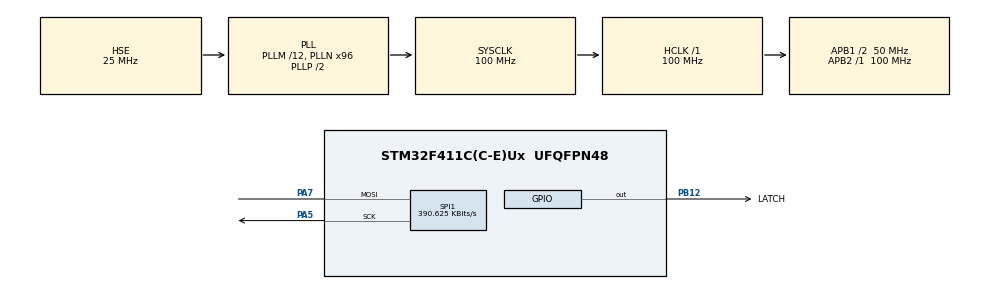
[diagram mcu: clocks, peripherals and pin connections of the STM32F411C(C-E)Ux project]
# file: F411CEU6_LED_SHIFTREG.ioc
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Mcu.Family=STM32F4
Mcu.Name=STM32F411C(C-E)Ux
Mcu.Package=UFQFPN48
NVIC.PriorityGroup=NVIC_PRIORITYGROUP_4
PA13.Mode=Serial_Wire
PA13.Signal=SYS_JTMS-SWDIO
PA14.Mode=Serial_Wire
PA14.Signal=SYS_JTCK-SWCLK
PA5.Mode=Simplex_Bidirectional_Master
PA5.Signal=SPI1_SCK
PA7.Mode=Simplex_Bidirectional_Master
PA7.Signal=SPI1_MOSI
PB12.GPIO_Label=LATCH
PB12.Signal=GPIO_Output
PH0\ -\ OSC_IN.Mode=HSE-External-Oscillator
PH0\ -\ OSC_IN.Signal=RCC_OSC_IN
PH1\ -\ OSC_OUT.Mode=HSE-External-Oscillator
PH1\ -\ OSC_OUT.Signal=RCC_OSC_OUT
ProjectManager.HeapSize=0x200
ProjectManager.StackSize=0x400
ProjectManager.TargetToolchain=STM32CubeIDE
RCC.48MHZClocksFreq_Value=50000000
RCC.AHBFreq_Value=100000000
RCC.APB1CLKDivider=RCC_HCLK_DIV2
RCC.APB1Freq_Value=50000000
RCC.APB1TimFreq_Value=100000000
RCC.APB2Freq_Value=100000000
RCC.APB2TimFreq_Value=100000000
RCC.CortexFreq_Value=100000000
RCC.HCLKFreq_Value=100000000
RCC.HSE_VALUE=25000000
RCC.HSI_VALUE=16000000
RCC.LSE_VALUE=32768
RCC.PLLM=12
RCC.PLLN=96
RCC.PLLSourceVirtual=RCC_PLLSOURCE_HSE
RCC.SYSCLKFreq_VALUE=100000000
RCC.SYSCLKSource=RCC_SYSCLKSOURCE_PLLCLK
RCC.VCOOutputFreq_Value=200000000
SPI1.BaudRatePrescaler=SPI_BAUDRATEPRESCALER_256
SPI1.CalculateBaudRate=390.625 KBits/s
SPI1.Direction=SPI_DIRECTION_1LINE
SPI1.Mode=SPI_MODE_MASTER
SPI1.VirtualType=VM_MASTER
board=custom

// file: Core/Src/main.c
/* USER CODE BEGIN Header */
/**
  ******************************************************************************
  * @file           : main.c
  * @brief          : Main program body
  ******************************************************************************
  * @attention
  *
  * Copyright (c) 2024 STMicroelectronics.
  * All rights reserved.
  *
  * This software is licensed under terms that can be found in the LICENSE file
  * in the root directory of this software component.
  * If no LICENSE file comes with this software, it is provided AS-IS.
  *
  ******************************************************************************
  */
/* USER CODE END Header */
#include "main.h"

/* USER CODE BEGIN Includes */
#include <string.h>
/* USER CODE END Includes */

SPI_HandleTypeDef hspi1;

/* USER CODE BEGIN PV */
uint8_t state;
uint16_t state2;
HAL_StatusTypeDef status;
/* USER CODE END PV */

void SystemClock_Config(void);
static void MX_GPIO_Init(void);
static void MX_SPI1_Init(void);

/* USER CODE BEGIN 0 */

// Shift out 8 bits to the shift register (LSB will be output A, MSB will be output H as in the datasheet)
// state = [H G F E ... A] in binary
void ShiftOut(uint8_t state) {
	status = HAL_SPI_Transmit(&hspi1, &state, 1, 10);

	HAL_GPIO_WritePin(LATCH_GPIO_Port, LATCH_Pin, GPIO_PIN_RESET);
	HAL_GPIO_WritePin(LATCH_GPIO_Port, LATCH_Pin, GPIO_PIN_SET);
}

// Various method to test with a single digit 7-segment display

void TestSingleByteShift() {
  state = 0x0f;
  ShiftOut(state);
}

void TestIndividualBit() {
	state = 0x01;
	for(int i = 0; i < 8; i++) {
		ShiftOut(state);
		state = state << 1;
		HAL_Delay(500);
	}
}

// LED edges in the 7-segment display to turn on for the digits
const uint8_t digits[] = {
		0b00111111,  // 0 = {A, B, C, D, E, F}
		0b00000110,  // 1 = {B, C}
		0b01011011,  // 2 = {A, B, D, E, G }
		0b01001111,  // 3 = {A, B, C, D, G }
		0b01100110,  // 4 = {B, C, F, G }
		0b01101101,  // 5 = {A, C, D, F, G }
		0b01111101,  // 6 = {A, C, D, E, F, G }
		0b00000111,  // 7 = {A, B, C }
		0b01111111,  // 8 = {A, B, C, D, E, F, G }
		0b01101111,  // 9 = {A, B, D, E, G }
		// Unfortunately, we cannot do hexadecimal since B is indistinguishable from 8 and D from 0.
};

void TestDigits() {
	for(int d = 0; d < 10; d++) {
		state = digits[d];
		ShiftOut(state);
		HAL_Delay(500);
	}
}

void TestAllByteShift() {
	for(state = 0x00; state <= 0xff; state++) {
	  ShiftOut(state);
	  HAL_Delay(100);
	}
}

// Shift out 2 bytes to the cascaded shift registers (one daisy chained to the another)
// state = [H1 G F E ... A1 | H2 G F E ... A2]
// where Ai, Bi, ..., Hi are the output of the i-th register. The 1st register is the one
// whose data pin 14 (SER) is connected to the MCU's MOSI. The second one received its data
// via the first's pin 9 (QH').
void ShiftOut2(uint16_t state) {
	status = HAL_SPI_Transmit(&hspi1, (uint8_t*)(&state), 2, 10);

	HAL_GPIO_WritePin(LATCH_GPIO_Port, LATCH_Pin, GPIO_PIN_RESET);
	HAL_GPIO_WritePin(LATCH_GPIO_Port, LATCH_Pin, GPIO_PIN_SET);
}

// Various functions to test daisy chained shift registers with a 4-digit 7-segment display and LED matrix
// Connection assumption:
//   * For 4-digit 7-segment dipslay:
//         1st shift register connects to digit LEDs (A, B, ..., DP)
//         2nd shift register A, B, C, D is connected to digit selection pin (pin 6, 8, 9, 12)
//   * For LED matrix:
//         1st shift register to the row pins
//         2nd shift register to the column pins

// Display the digit d at the digitNum (0..3 instead of 1..4)
void DisplayDigit(uint8_t d, uint8_t digitNum) {
	// We need to turn ONLY the bit for the digit off to ground it.
	// The remaining bits are kept high so that the LEDs are not on for them.
	uint8_t mask = 1 << digitNum;
	mask = ~mask;

	state2 = digits[d];
	state2 = (state2 << 8) | mask;
	ShiftOut2(state2);
}

// Render all digit slot one by one
// For example, 0 is displayed in the first digit slot, then second, then third, then forth.
// Then 1 is displayed in the first, ... etc.
void TestAllDigits() {
	for(uint8_t d = 0; d < 10; d++) {
		for(uint8_t n = 0; n < 4; n++) {
			DisplayDigit(d, n);
			HAL_Delay(1000);
		}
	}
}

// Quickly display 4-digit for "persistence of vision" (switching 1ms between digits)
// Note: d[s] is the most significant digit, d[3] is the least significant one
void Display4DigitNum(uint8_t d[4], uint8_t s) {
	for(uint8_t i = s; i < 4; i++) {
		DisplayDigit(d[i], i);
		HAL_Delay(1);
	}
}

void TestCounting() {
	uint8_t d[4];
	for(int value = 0; value <= 9999; value++) {
		int x = value;
		// Note that the ordering of digits on the 7-segment display is in reverse order
		// with the 1st being the most significant digit and the 4-th the least one.
		d[3] = x % 10; // unit digit
		x = x / 10;
		d[2] = x % 10; // ten digit
		x = x / 10;
		d[1] = x % 10;
		d[0] = x / 10;

		// Find the start digit (the actual most significant digit)
		uint8_t s = 0;
		for(s = 0; s < 3; s++) {
			if (d[s] != 0)
				break;
		}

		// Loop 200 times to keep the digit on display for ~200ms
		for(int c = 0; c < 200; c++) {
			Display4DigitNum(d, s);
		}

		// HAL_Delay(50);
	}
}

// Turn a single pixel on the 8x8 LED matrix
// Row and Column are indexed from 0 to 7 corresponding to 1..8 as in the datasheet of the unit
void DisplaySinglePixel(uint8_t row, uint8_t col) {
	// To turn the row-i column-j pixels on, we need to input HIGH (VCC) to the pin Ri and LOW (GND) to Cj.
	// This way, electricity will flow through the LED at (i, j).

	uint8_t mask = 1 << col;
	mask = ~mask;

	state2 = 1 << row;
	state2 = (state2 << 8) | mask;

	ShiftOut2(state2);
}

// Light up all pixels of the LED matrix one by one
void TestPixels() {
	for(uint8_t row = 0; row < 8; row++) {
		for(uint8_t col = 0; col < 8; col++) {
			DisplaySinglePixel(row, col);
			HAL_Delay(200);
		}
	}
}

// Render a bitmap where bitmap[i] is the i-th row (assumed already inverted for now)
// Once again we exploit persistence of vision: we render row-by-row with 1ms delay between rows
void RenderBitmap(uint8_t bitmap[8]) {
	for(uint8_t row = 0; row < 8; row++) {
		uint8_t mask = ~bitmap[row]; // Output LOW to the selected columns on the given row

		state2 = 1 << row;
		state2 = (state2 << 8) | mask;

		ShiftOut2(state2);

		HAL_Delay(1);
	}
}

const uint8_t infiniteBitmap[8] = {
	0b00000000,
	0b00000000,
	0b01100110,
	0b10011001,
	0b10011001,
	0b01100110,
	0b00000000,
	0b00000000
};

void TestBitmap() {
	for(int i = 0; i < 100; i++) {
		RenderBitmap(infiniteBitmap);
	}
}

const uint8_t leftArrowBitmap[8] = {
	0b00000000,
	0b00001000,
	0b00001100,
	0b01111110,
	0b01111111,
	0b01111110,
	0b00001100,
	0b00001000
};

uint8_t leftArrowBitmapTranslated[8];

void TestAnimation() {
	// Reset the current image
	memcpy(leftArrowBitmapTranslated, leftArrowBitmap, sizeof(leftArrowBitmap));

	for(int i = 0; i < 8; i++) {
		// Render the translated image for a bit of time before moving to the next frame
		for(int i = 0; i < 20; i++) {
			RenderBitmap(leftArrowBitmapTranslated);
		}

		// Shift all rows to the right to produce animation
		for(int r = 0; r < 8; r++) {
			leftArrowBitmapTranslated[r] = leftArrowBitmapTranslated[r] >> 1;
		}
	}
}
/* USER CODE END 0 */

int main(void)
{

  /* MCU Configuration--------------------------------------------------------*/

  /* Reset of all peripherals, Initializes the Flash interface and the Systick. */
  HAL_Init();

  /* Configure the system clock */
  SystemClock_Config();

  /* Initialize all configured peripherals */
  MX_GPIO_Init();
  MX_SPI1_Init();
  /* USER CODE BEGIN 2 */
  // TestSingleByteShift();
  /* USER CODE END 2 */

  /* Infinite loop */
  while (1)
  {

    /* USER CODE BEGIN 3 */
	// TestDigits();
	// TestAllByteShift();

	// TestAllDigits();
	// TestCounting();

	// TestPixels();
	// TestBitmap();
	TestAnimation();
  }
  /* USER CODE END 3 */
}

void SystemClock_Config(void)
{
  RCC_OscInitTypeDef RCC_OscInitStruct = {0};
  RCC_ClkInitTypeDef RCC_ClkInitStruct = {0};

  /** Configure the main internal regulator output voltage
  */
  __HAL_RCC_PWR_CLK_ENABLE();
  __HAL_PWR_VOLTAGESCALING_CONFIG(PWR_REGULATOR_VOLTAGE_SCALE1);

  /** Initializes the RCC Oscillators according to the specified parameters
  * in the RCC_OscInitTypeDef structure.
  */
  RCC_OscInitStruct.OscillatorType = RCC_OSCILLATORTYPE_HSE;
  RCC_OscInitStruct.HSEState = RCC_HSE_ON;
  RCC_OscInitStruct.PLL.PLLState = RCC_PLL_ON;
  RCC_OscInitStruct.PLL.PLLSource = RCC_PLLSOURCE_HSE;
  RCC_OscInitStruct.PLL.PLLM = 12;
  RCC_OscInitStruct.PLL.PLLN = 96;
  RCC_OscInitStruct.PLL.PLLP = RCC_PLLP_DIV2;
  RCC_OscInitStruct.PLL.PLLQ = 4;
  if (HAL_RCC_OscConfig(&RCC_OscInitStruct) != HAL_OK)
  {
    Error_Handler();
  }

  /** Initializes the CPU, AHB and APB buses clocks
  */
  RCC_ClkInitStruct.ClockType = RCC_CLOCKTYPE_HCLK|RCC_CLOCKTYPE_SYSCLK
                              |RCC_CLOCKTYPE_PCLK1|RCC_CLOCKTYPE_PCLK2;
  RCC_ClkInitStruct.SYSCLKSource = RCC_SYSCLKSOURCE_PLLCLK;
  RCC_ClkInitStruct.AHBCLKDivider = RCC_SYSCLK_DIV1;
  RCC_ClkInitStruct.APB1CLKDivider = RCC_HCLK_DIV2;
  RCC_ClkInitStruct.APB2CLKDivider = RCC_HCLK_DIV1;

  if (HAL_RCC_ClockConfig(&RCC_ClkInitStruct, FLASH_LATENCY_3) != HAL_OK)
  {
    Error_Handler();
  }
}

static void MX_SPI1_Init(void)
{

  /* SPI1 parameter configuration*/
  hspi1.Instance = SPI1;
  hspi1.Init.Mode = SPI_MODE_MASTER;
  hspi1.Init.Direction = SPI_DIRECTION_1LINE;
  hspi1.Init.DataSize = SPI_DATASIZE_8BIT;
  hspi1.Init.CLKPolarity = SPI_POLARITY_LOW;
  hspi1.Init.CLKPhase = SPI_PHASE_1EDGE;
  hspi1.Init.NSS = SPI_NSS_SOFT;
  hspi1.Init.BaudRatePrescaler = SPI_BAUDRATEPRESCALER_256;
  hspi1.Init.FirstBit = SPI_FIRSTBIT_MSB;
  hspi1.Init.TIMode = SPI_TIMODE_DISABLE;
  hspi1.Init.CRCCalculation = SPI_CRCCALCULATION_DISABLE;
  hspi1.Init.CRCPolynomial = 10;
  if (HAL_SPI_Init(&hspi1) != HAL_OK)
  {
    Error_Handler();
  }

}

static void MX_GPIO_Init(void)
{
  GPIO_InitTypeDef GPIO_InitStruct = {0};

  /* GPIO Ports Clock Enable */
  __HAL_RCC_GPIOH_CLK_ENABLE();
  __HAL_RCC_GPIOA_CLK_ENABLE();
  __HAL_RCC_GPIOB_CLK_ENABLE();

  /*Configure GPIO pin Output Level */
  HAL_GPIO_WritePin(LATCH_GPIO_Port, LATCH_Pin, GPIO_PIN_RESET);

  /*Configure GPIO pin : LATCH_Pin */
  GPIO_InitStruct.Pin = LATCH_Pin;
  GPIO_InitStruct.Mode = GPIO_MODE_OUTPUT_PP;
  GPIO_InitStruct.Pull = GPIO_NOPULL;
  GPIO_InitStruct.Speed = GPIO_SPEED_FREQ_LOW;
  HAL_GPIO_Init(LATCH_GPIO_Port, &GPIO_InitStruct);

}

void Error_Handler(void)
{
  __disable_irq();
  while (1)
  {
  }
}
